# AT32F403Axx_v2 register map
Vendor: Keil; Series: AT32F403A; File version: 1.0
CPU: CM4 r0p1, little endian, no MPU, FPU, 4 interrupt priority bits
Registers are 32-bit, read-write, reset 0x0 unless marked. A register's access mark holds for its fields unless they carry their own. Offsets are from the block's base; [hi:lo] are bit positions; lines under a group give offsets from that group; {n}, {i} and the like mark numbered series.

## ADC1 — Analog to digital converter
Base 0x40012400
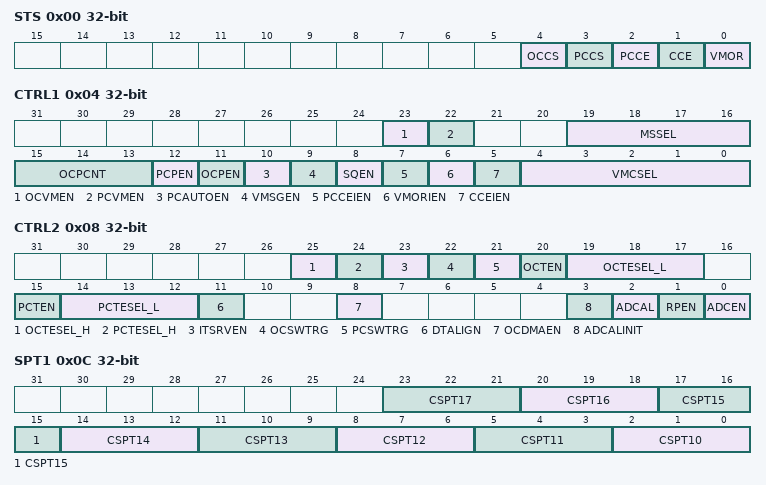
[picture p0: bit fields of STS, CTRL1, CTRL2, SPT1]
0x00 STS — status register
  [4] OCCS — Ordinary channel conversion start flag
  [3] PCCS — Preempted channel conversion start flag
  [2] PCCE — Preempted channels conversion end flag
  [1] CCE — Channels conversion end flag
  [0] VMOR — Voltage monitoring out of range flag
0x04 CTRL1 — control register 1
  [23] OCVMEN — Voltage monitoring enable on ordinary channels
  [22] PCVMEN — Voltage monitoring enable on preempted channels
  [19:16] MSSEL — Master slave mode select
  [15:13] OCPCNT — Partitioned mode conversion count of ordinary channels
  [12] PCPEN — Partitioned mode enable on preempted channels
  [11] OCPEN — Partitioned mode enable on ordinary channels
  [10] PCAUTOEN — Preempted group automatic conversion enable after ordinary group
  [9] VMSGEN — Voltage monitoring enable on a single channel
  [8] SQEN — Sequence mode enable
  [7] PCCEIEN — Conversion end interrupt enable for preempted channels
  [6] VMORIEN — Voltage monitoring out of range interrupt enable
  [5] CCEIEN — Channel conversion end interrupt enable
  [4:0] VMCSEL — Voltage monitoring channel select
0x08 CTRL2 — control register 2
  [25] OCTESEL_H — High bit of trigger event select for ordinary channels conversion
  [24] PCTESEL_H — High bit of trigger event select for preempted channels conversion
  [23] ITSRVEN — Internal temperature sensor and VINTRV enable
  [22] OCSWTRG — Conversion trigger by software of ordinary channels
  [21] PCSWTRG — Conversion trigger by software of preempted channels
  [20] OCTEN — Trigger mode enable for ordinary channels conversion
  [19:17] OCTESEL_L — Low bit of trigger event select for ordinary channels conversion
  [15] PCTEN — Trigger mode enable for preempted channels conversion
  [14:12] PCTESEL_L — Low bit of trigger event select for preempted channels conversion
  [11] DTALIGN — Data alignment
  [8] OCDMAEN — DMA transfer enable of ordinary channels
  [3] ADCALINIT — initialize A/D calibration
  [2] ADCAL — A/D Calibration
  [1] RPEN — Repeat mode enable
  [0] ADCEN — A/D converter enable
0x0C SPT1 — sample time register 1
  [3n-28:3n-30] CSPT{n} (n=10..17) — Selection sample time of channel ADC_IN{n}
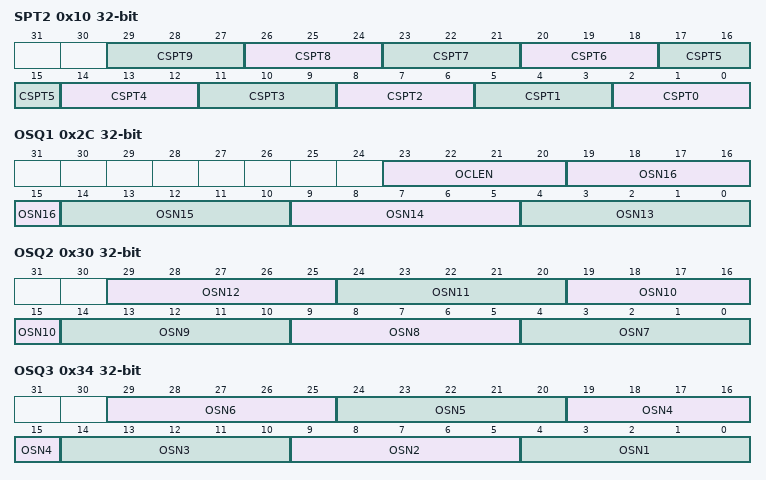
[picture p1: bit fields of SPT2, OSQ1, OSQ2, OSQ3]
0x10 SPT2 — sample time register 2
  [3n+2:3n] CSPT{n} (n=0..9) — Selection sample time of channel ADC_IN{n}
{0x10+4i} PCDTO{i} (i=1..4) — Preempted channel {i} data offset register
  [11:0] PCDTO{i} — Data offset for Preempted channel {i}
0x24 VMHB reset 0xFFF — Voltage monitoring high boundary register
  [11:0] VMHB — Voltage monitoring high boundary
0x28 VMLB — Voltage monitoring low boundary register
  [11:0] VMLB — Voltage monitoring low boundary
0x2C OSQ1 — Ordinary sequence register 1
  [23:20] OCLEN — Ordinary conversion sequence length
  [5n-61:5n-65] OSN{n} (n=13..16) — Number of {n}th conversion in ordinary sequence
0x30 OSQ2 — Ordinary sequence register 2
  [29:25] OSN12 — Number of 12th conversion in ordinary sequence
  [24:20] OSN11 — Number of 11th conversion in ordinary sequence
  [19:15] OSN10 — Number of 10th conversion in ordinary sequence
  [14:10] OSN9 — Number of 8th conversion in ordinary sequence
  [9:5] OSN8 — Number of 7th conversion in ordinary sequence
  [4:0] OSN7 — Number of 13th conversion in ordinary sequence
0x34 OSQ3 — Ordinary sequence register 3
  [29:25] OSN6 — Number of 6th conversion in ordinary sequence
  [24:20] OSN5 — Number of 5th conversion in ordinary sequence
  [19:15] OSN4 — Number of 4th conversion in ordinary sequence
  [14:10] OSN3 — number of 3rd conversion in ordinary sequence
  [9:5] OSN2 — Number of 2nd conversion in ordinary sequence
  [4:0] OSN1 — Number of 1st conversion in ordinary sequence
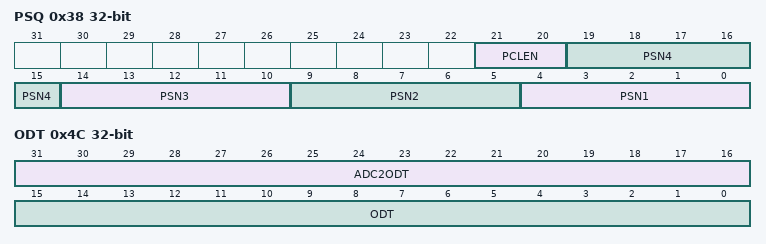
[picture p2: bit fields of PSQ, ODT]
0x38 PSQ — Preempted sequence register
  [21:20] PCLEN — Preempted conversion sequence length
  [19:15] PSN4 — Number of 4th conversion in Preempted sequence
  [14:10] PSN3 — Number of 3rd conversion in Preempted sequence
  [9:5] PSN2 — Number of 2nd conversion in Preempted sequence
  [4:0] PSN1 — Number of 1st conversion in Preempted sequence
{0x38+4i} PDT{i} ro (i=1..4) — Preempted data register {i}
  [15:0] PDT{i} — Preempted data
0x4C ODT ro — Ordinary data register
  [31:16] ADC2ODT — ADC2 conversion data of ordinary channel
  [15:0] ODT — Conversion data of ordinary channel

## ADC2 — Analog to digital converter
Base 0x40012800
Registers as ADC1; these are added or differ:
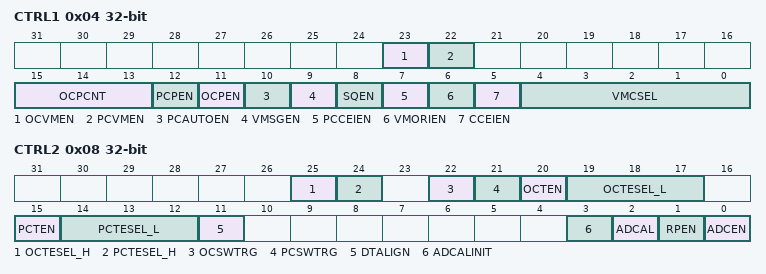
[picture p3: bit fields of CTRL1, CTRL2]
0x04 CTRL1 — control register 1
  [23] OCVMEN — Voltage monitoring enable on ordinary channels
  [22] PCVMEN — Voltage monitoring enable on preempted channels
  [15:13] OCPCNT — Partitioned mode conversion count of ordinary channels
  [12] PCPEN — Partitioned mode enable on preempted channels
  [11] OCPEN — Partitioned mode enable on ordinary channels
  [10] PCAUTOEN — Preempted group automatic conversion enable after ordinary group
  [9] VMSGEN — Voltage monitoring enable on a single channel
  [8] SQEN — Sequence mode enable
  [7] PCCEIEN — Conversion end interrupt enable for preempted channels
  [6] VMORIEN — Voltage monitoring out of range interrupt enable
  [5] CCEIEN — Channel conversion end interrupt enable
  [4:0] VMCSEL — Voltage monitoring channel select
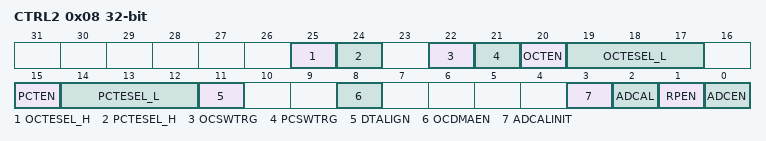
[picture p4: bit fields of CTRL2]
0x08 CTRL2 — control register 2
  [25] OCTESEL_H — High bit of trigger event select for ordinary channels conversion
  [24] PCTESEL_H — High bit of trigger event select for preempted channels conversion
  [22] OCSWTRG — Conversion trigger by software of ordinary channels
  [21] PCSWTRG — Conversion trigger by software of preempted channels
  [20] OCTEN — Trigger mode enable for ordinary channels conversion
  [19:17] OCTESEL_L — Low bit of trigger event select for ordinary channels conversion
  [15] PCTEN — Trigger mode enable for preempted channels conversion
  [14:12] PCTESEL_L — Low bit of trigger event select for preempted channels conversion
  [11] DTALIGN — Data alignment
  [3] ADCALINIT — initialize A/D calibration
  [2] ADCAL — A/D Calibration
  [1] RPEN — Repeat mode enable
  [0] ADCEN — A/D converter enable
0x4C ODT ro — Ordinary data register
  [15:0] ODT — Conversion data of ordinary channel

## ADC3 — Analog to digital converter
Base 0x40013C00
Registers as ADC2; these are added or differ:
0x08 CTRL2 — control register 2
  [25] OCTESEL_H — High bit of trigger event select for ordinary channels conversion
  [24] PCTESEL_H — High bit of trigger event select for preempted channels conversion
  [22] OCSWTRG — Conversion trigger by software of ordinary channels
  [21] PCSWTRG — Conversion trigger by software of preempted channels
  [20] OCTEN — Trigger mode enable for ordinary channels conversion
  [19:17] OCTESEL_L — Low bit of trigger event select for ordinary channels conversion
  [15] PCTEN — Trigger mode enable for preempted channels conversion
  [14:12] PCTESEL_L — Low bit of trigger event select for preempted channels conversion
  [11] DTALIGN — Data alignment
  [8] OCDMAEN — DMA transfer enable of ordinary channels
  [3] ADCALINIT — initialize A/D calibration
  [2] ADCAL — A/D Calibration
  [1] RPEN — Repeat mode enable
  [0] ADCEN — A/D converter enable

## Notices in the file
Copyright (C) 2012-2014 ARM Limited. All rights reserved.
Purpose: System Viewer Description (SVD) Example (Schema Version 1.1)
This is a description of a none-existent and incomplete device
for demonstration purposes only.
Redistribution and use in source and binary forms, with or without
modification, are permitted provided that the following conditions are met:
- Redistributions of source code must retain the above copyright
notice, this list of conditions and the following disclaimer.
- Redistributions in binary form must reproduce the above copyright
notice, this list of conditions and the following disclaimer in the
documentation and/or other materials provided with the distribution.
- Neither the name of ARM nor the names of its contributors may be used
to endorse or promote products derived from this software without
specific prior written permission.
THIS SOFTWARE IS PROVIDED BY THE COPYRIGHT HOLDERS AND CONTRIBUTORS "AS IS"
AND ANY EXPRESS OR IMPLIED WARRANTIES, INCLUDING, BUT NOT LIMITED TO, THE
IMPLIED WARRANTIES OF MERCHANTABILITY AND FITNESS FOR A PARTICULAR PURPOSE
ARE DISCLAIMED. IN NO EVENT SHALL COPYRIGHT HOLDERS AND CONTRIBUTORS BE
LIABLE FOR ANY DIRECT, INDIRECT, INCIDENTAL, SPECIAL, EXEMPLARY, OR
CONSEQUENTIAL DAMAGES (INCLUDING, BUT NOT LIMITED TO, PROCUREMENT OF
SUBSTITUTE GOODS OR SERVICES; LOSS OF USE, DATA, OR PROFITS; OR BUSINESS
INTERRUPTION) HOWEVER CAUSED AND ON ANY THEORY OF LIABILITY, WHETHER IN
CONTRACT, STRICT LIABILITY, OR TORT (INCLUDING NEGLIGENCE OR OTHERWISE)
ARISING IN ANY WAY OUT OF THE USE OF THIS SOFTWARE, EVEN IF ADVISED OF THE
POSSIBILITY OF SUCH DAMAGE.
